VERSION "manually crafted"

NS_ :

BS_:

BU_:

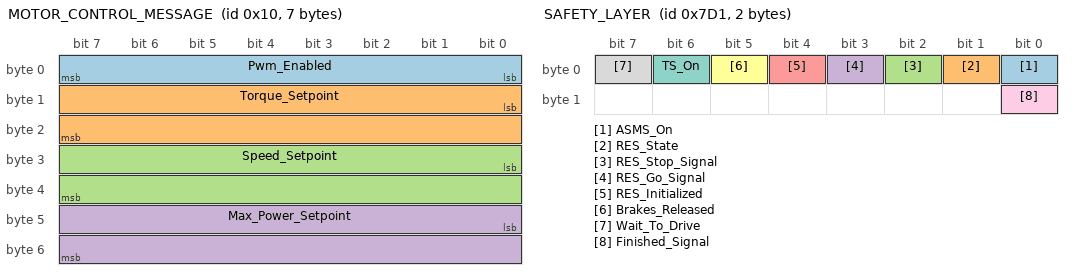
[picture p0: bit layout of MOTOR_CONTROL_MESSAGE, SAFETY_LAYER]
BO_ 16 MOTOR_CONTROL_MESSAGE: 7 Vector__XXX
 SG_ Pwm_Enabled : 0|8@1+ (1,0) [0|0] "" Vector__XXX
 SG_ Torque_Setpoint : 8|16@1+ (1,0) [0|0] "" Vector__XXX
 SG_ Speed_Setpoint : 24|16@1+ (1,0) [0|0] "" Vector__XXX
 SG_ Max_Power_Setpoint : 40|16@1+ (1,0) [0|0] "" Vector__XXX

BO_ 31 FRONT_NODE_STATUS: 2 Vector__XXX
 SG_ Counter : 0|8@1- (1,0) [0|0] "" Vector__XXX
 SG_ Ready_To_Drive : 8|8@1- (1,0) [0|0] "" Vector__XXX

BO_ 32 REAR_NODE_STATUS: 2 Vector__XXX
 SG_ Counter : 0|8@1- (1,0) [0|0] "" Vector__XXX
 SG_ Ready_To_Drive : 8|8@1- (1,0) [0|0] "" Vector__XXX

BO_ 33 AUTONOMOUS_NODE_STATUS: 2 Vector__XXX
 SG_ Counter : 0|8@1- (1,0) [0|0] "" Vector__XXX
 SG_ Ready_To_Drive : 8|8@1- (1,0) [0|0] "" Vector__XXX

BO_ 34 AMS_STATUS: 2 Vector__XXX
 SG_ Counter : 0|8@1- (1,0) [0|0] "" Vector__XXX
 SG_ Ready_To_Drive : 8|8@1- (1,0) [0|0] "" Vector__XXX

BO_ 50 APPS: 5 Vector__XXX
 SG_ Throttle_Percentage : 0|32@1+ (1,0) [0.0|100.0] "per" Vector__XXX
 SG_ Apps_Fault : 32|1@1+ (1,0) [0|0] "" Vector__XXX

BO_ 200 TEST_CAN_MESSAGE_1: 1 Vector__XXX
 SG_ Test_Message : 0|8@1+ (1,0) [0|0] "" Vector__XXX

BO_ 201 TEST_CAN_MESSAGE_2: 1 Vector__XXX
 SG_ Test_Message : 0|8@1+ (1,0) [0|0] "" Vector__XXX

BO_ 202 TEST_CAN_MESSAGE_3: 1 Vector__XXX
 SG_ Test_Message : 0|8@1+ (1,0) [0|0] "" Vector__XXX

BO_ 2001 SAFETY_LAYER: 2 Vector__XXX
 SG_ ASMS_On : 0|1@1+ (1,0) [0|1] "" Vector__XXX
 SG_ RES_State : 1|1@1+ (1,0) [0|1] "" Vector__XXX
 SG_ RES_Stop_Signal : 2|1@1+ (1,0) [0|1] "" Vector__XXX
 SG_ RES_Go_Signal : 3|1@1+ (1,0) [0|1] "" Vector__XXX
 SG_ RES_Initialized : 4|1@1+ (1,0) [0|1] "" Vector__XXX
 SG_ Brakes_Released : 5|1@1+ (1,0) [0|0] "" Vector__XXX
 SG_ TS_On : 6|1@1+ (1,0) [0|0] "" Vector__XXX
 SG_ Wait_To_Drive : 7|1@1+ (1,0) [0|0] "" Vector__XXX
 SG_ Finished_Signal : 8|1@1+ (1,0) [0|0] "" Vector__XXX

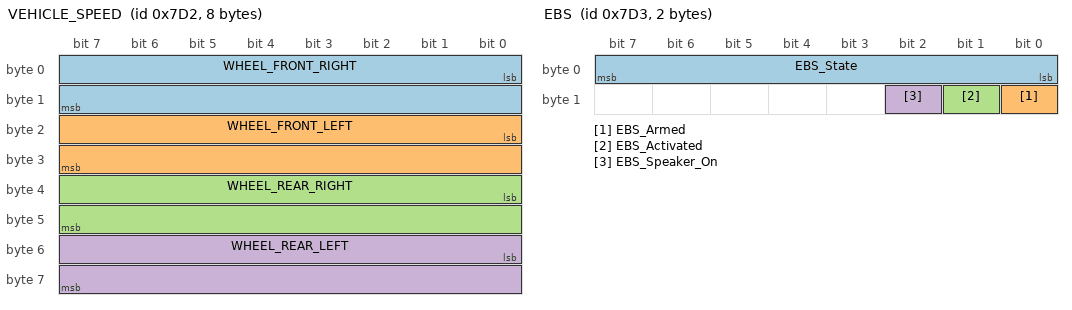
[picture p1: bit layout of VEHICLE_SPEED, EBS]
BO_ 2002 VEHICLE_SPEED: 8 Vector__XXX
 SG_ WHEEL_FRONT_RIGHT : 0|16@1+ (1,0) [0|0] "" Vector__XXX
 SG_ WHEEL_FRONT_LEFT : 16|16@1+ (1,0) [0|0] "" Vector__XXX
 SG_ WHEEL_REAR_RIGHT : 32|16@1+ (1,0) [0|0] "" Vector__XXX
 SG_ WHEEL_REAR_LEFT : 48|16@1+ (1,0) [0|0] "" Vector__XXX

BO_ 2003 EBS: 2 Vector__XXX
 SG_ EBS_State : 0|8@1+ (1,0) [0|0] "" Vector__XXX
 SG_ EBS_Armed : 8|1@1+ (1,0) [0|0] "" Vector__XXX
 SG_ EBS_Activated : 9|1@1+ (1,0) [0|0] "" Vector__XXX
 SG_ EBS_Speaker_On : 10|1@1+ (1,0) [0|0] "" Vector__XXX

BO_ 2005 AS_MISSION: 1 Vector__XXX
 SG_ Mission_Select : 0|8@1+ (1,0) [0|0] "" Vector__XXX

SIG_VALTYPE_ 50 Throttle_Percentage : 1;
SIG_VALTYPE_ 1553 Rotation_Z : 1;
